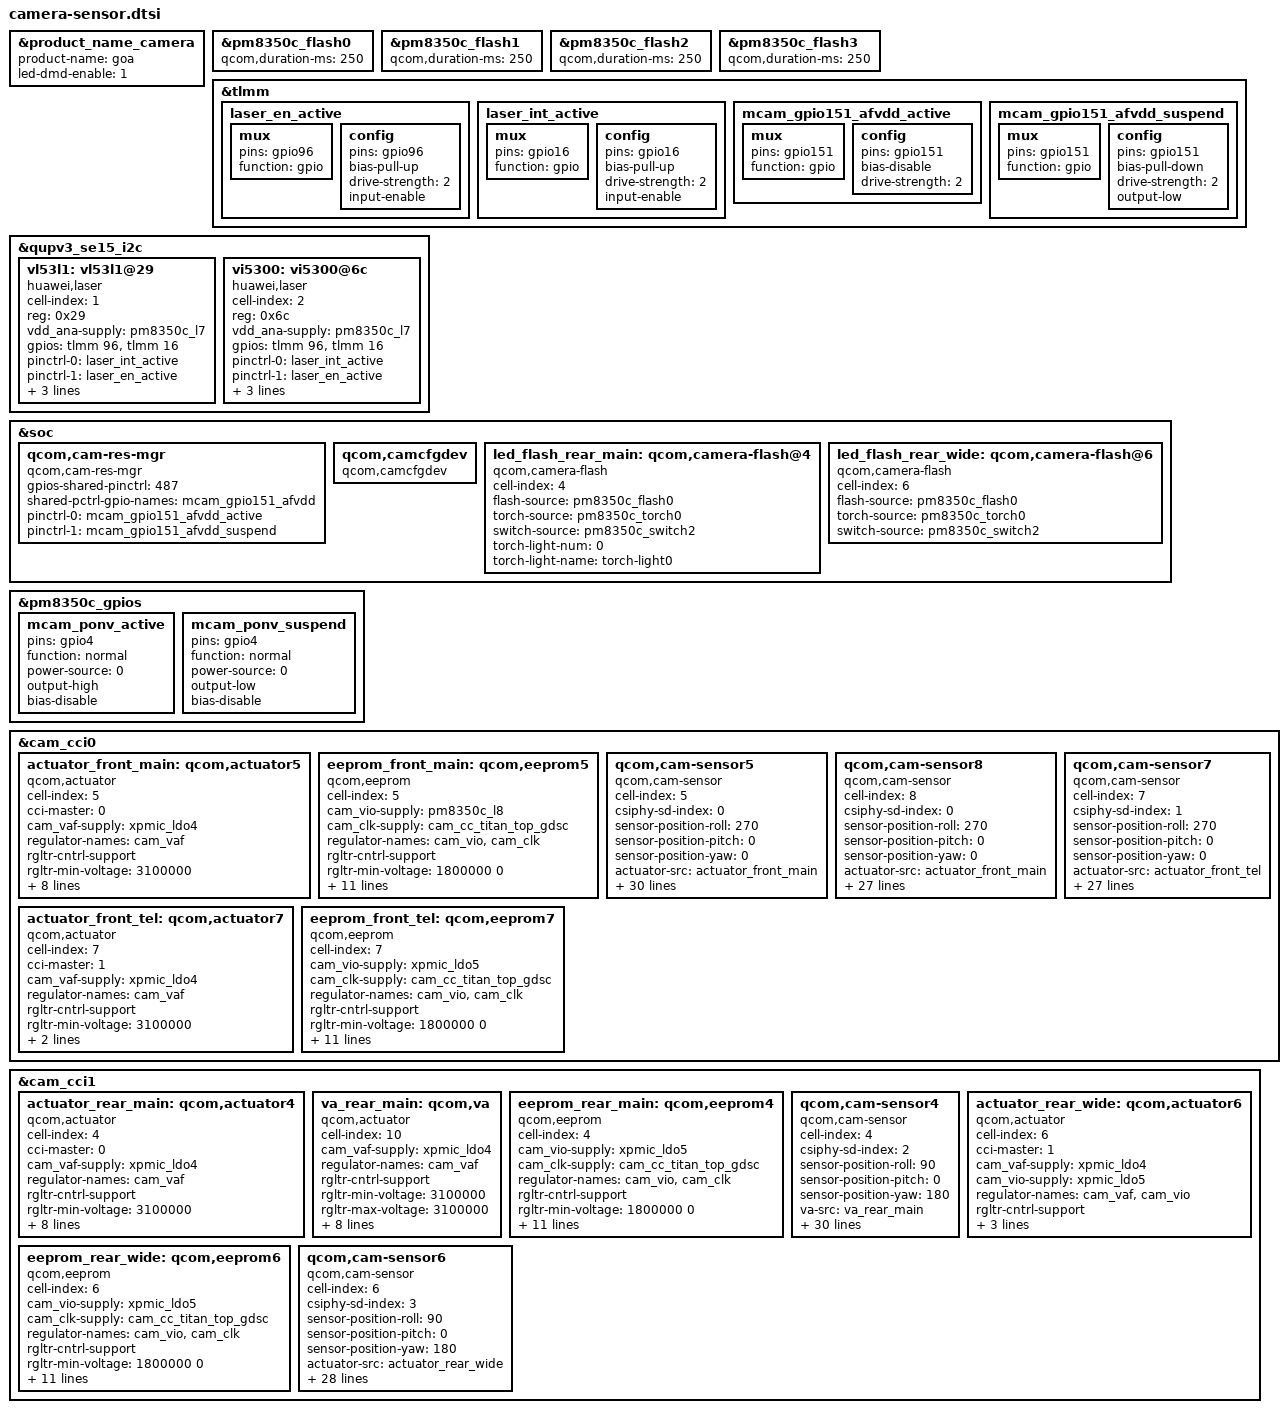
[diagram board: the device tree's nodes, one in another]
#include <dt-bindings/clock/qcom,camcc-yupik.h>
#include "camera-sensor-7250b.dtsi"

&product_name_camera {
	product-name = "goa";
	led-dmd-enable = <1>;
};

&pm8350c_flash0 {
	qcom,duration-ms = <250>;
};

&pm8350c_flash1 {
	qcom,duration-ms = <250>;
};

&pm8350c_flash2 {
	qcom,duration-ms = <250>;
};

&pm8350c_flash3 {
	qcom,duration-ms = <250>;
};

&tlmm {
	laser_en_active: laser_en_active {
		/* laser en pin */
		mux {
			pins = "gpio96";
			function = "gpio";
		};

		config {
			pins = "gpio96";
			bias-pull-up; /* PULL UP */
			drive-strength = <2>; /* 2 MA */
			input-enable;
		};
	};

	laser_int_active: laser_int_active {
		/* laser int pin */
		mux {
			pins = "gpio16";
			function = "gpio";
		};

		config {
			pins = "gpio16";
			bias-pull-up; /* PULL UP */
			drive-strength = <2>; /* 2 MA */
			input-enable;
		};
	};

	mcam_gpio151_afvdd_active: mcam_gpio151_afvdd_active {
		mux {
			pins = "gpio151";
			function = "gpio";
		};

		config {
			pins = "gpio151";
			bias-disable; /* No PULL */
			drive-strength = <2>; /* 2 MA */
		};
	};

	mcam_gpio151_afvdd_suspend: mcam_gpio151_afvdd_suspend {
		mux {
			pins = "gpio151";
			function = "gpio";
		};

		config {
			pins = "gpio151";
			bias-pull-down; /* PULL DOWN */
			drive-strength = <2>; /* 2 MA */
			output-low;
		};
	};
};

/* laser */
&qupv3_se15_i2c {
	status = "ok";

	vl53l1: vl53l1@29 {
		cell-index = <1>;
		compatible = "huawei,laser";
		reg = <0x29>;
		vdd_ana-supply = <&pm8350c_l7>;
		gpios = <&tlmm 96 0>,
			<&tlmm 16 0>;
		pinctrl-names = "laser_int_active", "laser_en_active";
		pinctrl-0 = <&laser_int_active>;
		pinctrl-1 = <&laser_en_active>;
		gpio-req-tbl-num = <0>;
		gpio-req-tbl-flags = <0>;
		gpio-req-tbl-label = "CAM_VAF0";
		status = "ok";
	};

	vi5300: vi5300@6c {
		cell-index = <2>;
		compatible = "huawei,laser";
		reg = <0x6c>;
		vdd_ana-supply = <&pm8350c_l7>;
		gpios = <&tlmm 96 0>,
			<&tlmm 16 0>;
		pinctrl-names = "laser_int_active", "laser_en_active";
		pinctrl-0 = <&laser_int_active>;
		pinctrl-1 = <&laser_en_active>;
		gpio-req-tbl-num = <0>;
		gpio-req-tbl-flags = <0>;
		gpio-req-tbl-label = "CAM_VAF0";
		status = "ok";
	};
};

&soc {
	qcom,cam-res-mgr {
		compatible = "qcom,cam-res-mgr";
		gpios-shared-pinctrl = <487>; /* 7315gpio offset is 336 */
		shared-pctrl-gpio-names = "mcam_gpio151_afvdd";
		pinctrl-names = "mcam_gpio151_afvdd_active", "mcam_gpio151_afvdd_suspend";
		pinctrl-0 = <&mcam_gpio151_afvdd_active>;
		pinctrl-1 = <&mcam_gpio151_afvdd_suspend>;
		status = "ok";
	};

	qcom,camcfgdev {
		compatible = "qcom,camcfgdev";
		status = "ok";
	};

	led_flash_rear_main: qcom,camera-flash@4 {
		cell-index = <4>;
		compatible = "qcom,camera-flash";
		flash-source = <&pm8350c_flash0>;
		torch-source = <&pm8350c_torch0>;
		switch-source = <&pm8350c_switch2>;
		torch-light-num = <0>;
		torch-light-name = "torch-light0";
		status = "ok";
	};

	led_flash_rear_wide: qcom,camera-flash@6 {
		cell-index = <6>;
		compatible = "qcom,camera-flash";
		flash-source = <&pm8350c_flash0>;
		torch-source = <&pm8350c_torch0>;
		switch-source = <&pm8350c_switch2>;
		status = "ok";
	};
};

&pm8350c_gpios {
	mcam_ponv_active: mcam_ponv_active {
		pins = "gpio4";
		function = "normal";
		power-source = <0>;
		output-high;
		bias-disable;
	};
	mcam_ponv_suspend: mcam_ponv_suspend {
		pins = "gpio4";
		function = "normal";
		power-source = <0>;
		output-low;
		bias-disable;
	};
};

/* cci0: i2c0 i2c1 */
&cam_cci0 {
	/* front main actuator */
	actuator_front_main: qcom,actuator5 {
		cell-index = <5>;
		compatible = "qcom,actuator";
		status = "ok";
		cci-master = <0>;
		cam_vaf-supply = <&xpmic_ldo4>;
		regulator-names = "cam_vaf";
		rgltr-cntrl-support;
		rgltr-min-voltage = <3100000>;
		rgltr-max-voltage = <3100000>;
		rgltr-load-current = <0>;
		gpio-no-mux = <0>;
		gpios = <&tlmm 151 0>; /* mcam_vavdd (afvdd) gpio151 */
		gpio-vaf-pwctrl = <0>;
		gpio-req-tbl-num = <0>;
		gpio-req-tbl-flags = <0>;
		gpio-req-tbl-label = "CAM_VAF_PWCTRL";
	};

	/* front main eeprom */
	eeprom_front_main: qcom,eeprom5 {
		cell-index = <5>; /* slotId 5 */
		compatible = "qcom,eeprom";
		cam_vio-supply = <&pm8350c_l8>;
		cam_clk-supply = <&cam_cc_titan_top_gdsc>;
		regulator-names = "cam_vio", "cam_clk";
		rgltr-cntrl-support;
		rgltr-min-voltage = <1800000 0>;
		rgltr-max-voltage = <1800000 0>;
		rgltr-load-current = <40000 0>;
		gpio-no-mux = <0>;
		gpios = <&tlmm 64 0>;
		gpio-req-tbl-num = <0>;
		gpio-req-tbl-flags = <1>;
		gpio-req-tbl-label = "CAMIF_MCLK0";
		cci-master = <0>;
		status = "ok";
		clocks = <&camcc CAM_CC_MCLK0_CLK>;
		clock-names = "cam_clk";
		clock-cntl-level = "nominal";
		clock-rates = <19200000>;
	};

	/* front main senosr */
	qcom,cam-sensor5 {
		cell-index = <5>; /* slotId 5 */
		compatible = "qcom,cam-sensor";
		csiphy-sd-index = <0>; /* phy0 */
		sensor-position-roll = <270>;
		sensor-position-pitch = <0>;
		sensor-position-yaw = <0>;
		actuator-src = <&actuator_front_main>;
		eeprom-src = <&eeprom_front_main>;
		sensor-mixed-pin = <0>;
		cam_vana-supply = <&xpmic_ldo7>; /* mcam avdd 2.85v */
		cam_vaf-supply = <&xpmic_ldo4>;    /* mcam afvdd 3.1v */
		cam_vdig-supply = <&xpmic_ldo1>; /* mcam dvdd 1.14v */
		cam_vio-supply = <&pm8350c_l8>; /* iovdd pm8350c l8 1.8v */
		cam_clk-supply = <&cam_cc_titan_top_gdsc>;
		regulator-names = "cam_vana", "cam_vaf", "cam_vdig", "cam_vio", "cam_clk";
		rgltr-cntrl-support;
		rgltr-min-voltage = <2850000 3100000 1140000 1800000 0>;
		rgltr-max-voltage = <2850000 3100000 1140000 1800000 0>;
		rgltr-load-current = <40000 0 40000 40000 0>; /* value? */
		gpio-no-mux = <0>;
		pinctrl-names = "cam_default", "cam_suspend";
		pinctrl-0 = <&cam_sensor_mclk0_active>;
		pinctrl-1 = <&cam_sensor_mclk0_suspend>;
		gpios = <&tlmm 64 0>, /* mclk0 gpio 64 */
			<&tlmm 20 0>, /* reset0 gpio 20 */
			<&pm8350c_gpios 4 0>; /* ponv 8350c(7350c) gpio 4 */
		gpio-reset = <1>;
		gpio-mixed1 = <2>;
		gpio-req-tbl-num = <0 1 2>;
		gpio-req-tbl-flags = <1 0 0>;
		gpio-req-tbl-label = "CAMIF_MCLK0",
					"CAM_RESET0",
					"CAM_MIXED1";
		cci-master = <0>; /* i2c0 */
		status = "ok";
		clocks = <&camcc CAM_CC_MCLK0_CLK>;
		clock-names = "cam_clk";
		clock-cntl-level = "nominal";
		clock-rates = <19200000>;
		ic_position = <1>; /* CAMERA_POSITION_FORE */
	};

	/* front swing senosr */
	qcom,cam-sensor8 {
		cell-index = <8>; /* slotId 8 */
		compatible = "qcom,cam-sensor";
		csiphy-sd-index = <0>; /* phy0 */
		sensor-position-roll = <270>;
		sensor-position-pitch = <0>;
		sensor-position-yaw = <0>;
		actuator-src = <&actuator_front_main>;
		eeprom-src = <&eeprom_front_main>;
		sensor-mixed-pin = <0>;
		cam_vana-supply = <&xpmic_ldo7>; /* mcam avdd 2.85v */
		cam_vdig-supply = <&xpmic_ldo1>; /* mcam dvdd 1.14v */
		cam_vio-supply = <&pm8350c_l8>; /* iovdd pm8350c l8 1.8v */
		cam_clk-supply = <&cam_cc_titan_top_gdsc>;
		regulator-names = "cam_vana", "cam_vdig", "cam_vio", "cam_clk";
		rgltr-cntrl-support;
		rgltr-min-voltage = <2850000 1140000 1800000 0>;
		rgltr-max-voltage = <2850000 1140000 1800000 0>;
		rgltr-load-current = <40000 40000 40000 0>; /* value? */
		gpio-no-mux = <0>;
		pinctrl-names = "cam_default", "cam_suspend";
		pinctrl-0 = <&cam_sensor_mclk0_active>;
		pinctrl-1 = <&cam_sensor_mclk0_suspend>;
		gpios = <&tlmm 64 0>, /* mclk0 gpio 64 */
			<&tlmm 20 0>, /* reset0 gpio 20 */
			<&pm8350c_gpios 4 0>; /* ponv 8350c(7350c) gpio 4 */
		gpio-reset = <1>;
		gpio-mixed1 = <2>;
		gpio-req-tbl-num = <0 1 2>;
		gpio-req-tbl-flags = <1 0 0>;
		gpio-req-tbl-label = "CAMIF_MCLK0",
					"CAM_RESET0",
					"CAM_MIXED1";
		cci-master = <0>; /* i2c0 */
		status = "ok";
		clocks = <&camcc CAM_CC_MCLK0_CLK>;
		clock-names = "cam_clk";
		clock-cntl-level = "nominal";
		clock-rates = <19200000>;
		ic_position = <4>; /* CAMERA_POSITION_FORE */
	};

	/* front tel actuator */
	actuator_front_tel: qcom,actuator7 {
		cell-index = <7>;
		compatible = "qcom,actuator";
		status = "ok";
		cci-master = <1>;
		cam_vaf-supply = <&xpmic_ldo4>;
		regulator-names = "cam_vaf";
		rgltr-cntrl-support;
		rgltr-min-voltage = <3100000>;
		rgltr-max-voltage = <3100000>;
		rgltr-load-current = <0>;
	};

	/* front tel eeprom */
	eeprom_front_tel: qcom,eeprom7 {
		cell-index = <7>; /* slotId 7 */
		compatible = "qcom,eeprom";
		cam_vio-supply = <&xpmic_ldo5>;
		cam_clk-supply = <&cam_cc_titan_top_gdsc>;
		regulator-names = "cam_vio", "cam_clk";
		rgltr-cntrl-support;
		rgltr-min-voltage = <1800000 0>;
		rgltr-max-voltage = <1800000 0>;
		rgltr-load-current = <40000 0>;
		gpio-no-mux = <0>;
		gpios = <&tlmm 65 0>;
		gpio-req-tbl-num = <0>;
		gpio-req-tbl-flags = <1>;
		gpio-req-tbl-label = "CAMIF_MCLK1";
		cci-master = <1>;
		status = "ok";
		clocks = <&camcc CAM_CC_MCLK1_CLK>;
		clock-names = "cam_clk";
		clock-cntl-level = "nominal";
		clock-rates = <19200000>;
	};

	/* front tel senosr */
	qcom,cam-sensor7 {
		cell-index = <7>; /* slotId 7 */
		compatible = "qcom,cam-sensor";
		csiphy-sd-index = <1>; /* phy1 */
		sensor-position-roll = <270>;
		sensor-position-pitch = <0>;
		sensor-position-yaw = <0>;
		actuator-src = <&actuator_front_tel>;
		eeprom-src = <&eeprom_front_tel>;
		cam_vana-supply = <&xpmic_ldo3>; /* mcam avdd 2.85v */
		cam_vio-supply = <&xpmic_ldo5>; /* mcam iovdd 1.8v */
		cam_vdig-supply = <&xpmic_ldo1>; /* mcam dvdd 1.14v */
		cam_vaf-supply = <&xpmic_ldo4>; /* afvdd pm8350c l11 3.1v */
		cam_clk-supply = <&cam_cc_titan_top_gdsc>;
		regulator-names = "cam_vana", "cam_vio", "cam_vdig","cam_vaf", "cam_clk";
		rgltr-cntrl-support;
		rgltr-min-voltage = <2850000 1800000 1140000 3100000 0>;
		rgltr-max-voltage = <2850000 1800000 1140000 3100000 0>;
		rgltr-load-current = <4000 4000 4000 0 0>; /* value? */
		gpio-no-mux = <0>;
		pinctrl-names = "cam_default", "cam_suspend";
		pinctrl-0 = <&cam_sensor_mclk1_active>;
		pinctrl-1 = <&cam_sensor_mclk1_suspend>;
		gpios = <&tlmm 65 0>, /* mclk1 gpio 65 */
			<&tlmm 21 0>; /* reset1 gpio 21 */
		gpio-reset = <1>;
		gpio-req-tbl-num = <0 1>;
		gpio-req-tbl-flags = <1 0>;
		gpio-req-tbl-label = "CAMIF_MCLK1",
					"CAM_RESET1";
		cci-master = <1>; /* i2c1 */
		status = "ok";
		clocks = <&camcc CAM_CC_MCLK1_CLK>;
		clock-names = "cam_clk";
		clock-cntl-level = "nominal";
		clock-rates = <19200000>;
		ic_position = <3>; /* CAMERA_POSITION_FORE_SECOND */
	};
};

/* cci1: i2c2、i2c3 */
&cam_cci1 {
	/* rear main actuator */
	actuator_rear_main: qcom,actuator4 {
		cell-index = <4>;
		compatible = "qcom,actuator";
		status = "ok";
		cci-master = <0>;
		cam_vaf-supply = <&xpmic_ldo4>;
		regulator-names = "cam_vaf";
		rgltr-cntrl-support;
		rgltr-min-voltage = <3100000>;
		rgltr-max-voltage = <3100000>;
		rgltr-load-current = <0>;
		gpio-no-mux = <0>;
		gpios = <&tlmm 151 0>; /* mcam_vavdd (afvdd) gpio151 */
		gpio-vaf-pwctrl = <0>;
		gpio-req-tbl-num = <0>;
		gpio-req-tbl-flags = <0>;
		gpio-req-tbl-label = "CAM_VAF_PWCTRL";
	};

	/* rear VAAF actuator */
	va_rear_main: qcom,va {
		cell-index = <10>; /* va cell-index is different from the index of all sensors */
		compatible = "qcom,actuator";
		cam_vaf-supply = <&xpmic_ldo4>;
		regulator-names = "cam_vaf";
		rgltr-cntrl-support;
		rgltr-min-voltage = <3100000>;
		rgltr-max-voltage = <3100000>;
		rgltr-load-current = <0>;
		gpio-no-mux = <0>;
		gpios = <&tlmm 33 0>; /* mcam_vavdd (afvdd) gpio33 */
		gpio-vaf-pwctrl = <0>;
		gpio-req-tbl-num = <0>;
		gpio-req-tbl-flags = <0>;
		gpio-req-tbl-label = "CAM_VAF_PWCTRL";
		cci-master = <0>;
		status = "ok";
	};

	/* rear main eeprrom */
	eeprom_rear_main: qcom,eeprom4 {
		cell-index = <4>; /* slotId 4 */
		compatible = "qcom,eeprom";
		cam_vio-supply = <&xpmic_ldo5>;
		cam_clk-supply = <&cam_cc_titan_top_gdsc>;
		regulator-names = "cam_vio", "cam_clk";
		rgltr-cntrl-support;
		rgltr-min-voltage = <1800000 0>;
		rgltr-max-voltage = <1800000 0>;
		rgltr-load-current = <40000 0>;
		gpio-no-mux = <0>;
		gpios = <&tlmm 66 0>;
		gpio-req-tbl-num = <0>;
		gpio-req-tbl-flags = <1>;
		gpio-req-tbl-label = "CAMIF_MCLK2";
		cci-master = <0>;
		status = "ok";
		clocks = <&camcc CAM_CC_MCLK2_CLK>;
		clock-names = "cam_clk";
		clock-cntl-level = "nominal";
		clock-rates = <19200000>;
	};

	/* rear main senosr */
	qcom,cam-sensor4 {
		cell-index = <4>; /* slotId 4 */
		compatible = "qcom,cam-sensor";
		csiphy-sd-index = <2>; /* phy2 */
		sensor-position-roll = <90>;
		sensor-position-pitch = <0>;
		sensor-position-yaw = <180>;
		va-src = <&va_rear_main>;
		led-flash-src = <&led_flash_rear_main>;
		actuator-src = <&actuator_rear_main>;
		eeprom-src = <&eeprom_rear_main>;
		cam_vana-supply = <&xpmic_ldo3>; /* mcam avdd 2.85v */
		cam_vio-supply = <&xpmic_ldo5>; /* mcam iovdd 1.8v */
		cam_vdig-supply = <&xpmic_ldo2>; /* mcam dvdd 1.14v */
		cam_vana1-supply = <&xpmic_ldo6>; /* mcam avdd 1.8v */
		cam_vaf-supply = <&xpmic_ldo4>;    /* afvdd 3.1v */
		cam_clk-supply = <&cam_cc_titan_top_gdsc>;
		regulator-names = "cam_vana", "cam_vio", "cam_vdig", "cam_vana1", "cam_vaf", "cam_clk";
		rgltr-cntrl-support;
		rgltr-min-voltage = <2850000 1800000 1140000 1800000 3100000 0>;
		rgltr-max-voltage = <2850000 1800000 1140000 1800000 3100000 0>;
		rgltr-load-current = <4000 4000 4000 40000 0 0>; /* value? */
		gpio-no-mux = <0>;
		pinctrl-names = "cam_default", "cam_suspend";
		pinctrl-0 = <&cam_sensor_mclk2_active>;
		pinctrl-1 = <&cam_sensor_mclk2_suspend>;
		gpios = <&tlmm 66 0>, /* mclk2 gpio 66 */
			<&tlmm 77 0>; /* reset2 gpio 77 */
		gpio-reset = <1>;
		gpio-req-tbl-num = <0 1>;
		gpio-req-tbl-flags = <1 0>;
		gpio-req-tbl-label = "CAMIF_MCLK2",
					"CAM_RESET2";
		cci-master = <0>; /* i2c2 */
		status = "ok";
		clocks = <&camcc CAM_CC_MCLK2_CLK>;
		clock-names = "cam_clk";
		clock-cntl-level = "nominal";
		clock-rates = <19200000>;
		ic_position = <0>; /* CAMERA_POSITION_REAR */
	};

	/* rear wide actuator */
	actuator_rear_wide: qcom,actuator6 {
		cell-index = <6>;
		compatible = "qcom,actuator";
		status = "ok";
		cci-master = <1>;
		cam_vaf-supply = <&xpmic_ldo4>;    /* mcam afvdd 3.1v */
		cam_vio-supply = <&xpmic_ldo5>; /* mcam iovdd 1.8v */
		regulator-names = "cam_vaf", "cam_vio";
		rgltr-cntrl-support;
		rgltr-min-voltage = <3100000 1800000>;
		rgltr-max-voltage = <3100000 1800000>;
		rgltr-load-current = <0 0>; /* value? */
	};

	/* rear wide eeprom */
	eeprom_rear_wide: qcom,eeprom6 {
		cell-index = <6>; /* slotId 6 */
		compatible = "qcom,eeprom";
		cam_vio-supply = <&xpmic_ldo5>;
		cam_clk-supply = <&cam_cc_titan_top_gdsc>;
		regulator-names = "cam_vio", "cam_clk";
		rgltr-cntrl-support;
		rgltr-min-voltage = <1800000 0>;
		rgltr-max-voltage = <1800000 0>;
		rgltr-load-current = <40000 0>;
		gpio-no-mux = <0>;
		gpios = <&tlmm 67 0>;
		gpio-req-tbl-num = <0>;
		gpio-req-tbl-flags = <1>;
		gpio-req-tbl-label = "CAMIF_MCLK3";
		cci-master = <1>;
		status = "ok";
		clocks = <&camcc CAM_CC_MCLK3_CLK>;
		clock-names = "cam_clk";
		clock-cntl-level = "nominal";
		clock-rates = <19200000>;
	};

	/* rear wide senosr */
	qcom,cam-sensor6 {
		cell-index = <6>; /* slotId 6 */
		compatible = "qcom,cam-sensor";
		csiphy-sd-index = <3>; /* phy3 */
		sensor-position-roll = <90>;
		sensor-position-pitch = <0>;
		sensor-position-yaw = <180>;
		actuator-src = <&actuator_rear_wide>;
		eeprom-src = <&eeprom_rear_wide>;
		led-flash-src = <&led_flash_rear_wide>;
		cam_vana-supply = <&xpmic_ldo3>; /* mcam avdd 2.85v */
		cam_vaf-supply = <&xpmic_ldo4>;    /* mcam afvdd 3.1v */
		cam_vio-supply = <&xpmic_ldo5>; /* mcam iovdd 1.8v */
		cam_vdig-supply = <&pm7325_l8>; /* dvdd pm7325 l8 1.216v*/
		cam_clk-supply = <&cam_cc_titan_top_gdsc>;
		regulator-names = "cam_vana", "cam_vaf", "cam_vio", "cam_vdig", "cam_clk";
		rgltr-cntrl-support;
		rgltr-min-voltage = <2850000 3100000 1800000 1216000 0>;
		rgltr-max-voltage = <2850000 3100000 1800000 1216000 0>;
		rgltr-load-current = <0 0 0 0 0>; /* value? */
		gpio-no-mux = <0>;
		pinctrl-names = "cam_default", "cam_suspend";
		pinctrl-0 = <&cam_sensor_mclk3_active>;
		pinctrl-1 = <&cam_sensor_mclk3_suspend>;
		gpios = <&tlmm 67 0>, /* mclk3 gpio 67 */
			<&tlmm 78 0>; /* reset3 gpio 78 */
		gpio-reset = <1>;
		gpio-req-tbl-num = <0 1>;
		gpio-req-tbl-flags = <1 0>;
		gpio-req-tbl-label = "CAMIF_MCLK3",
					"CAM_RESET3";
		cci-master = <1>; /* i2c3 */
		status = "ok";
		clocks = <&camcc CAM_CC_MCLK3_CLK>;
		clock-names = "cam_clk";
		clock-cntl-level = "nominal";
		clock-rates = <19200000>;
		ic_position = <2>; /* CAMERA_POSITION_REAR_SECOND */
	};
};
